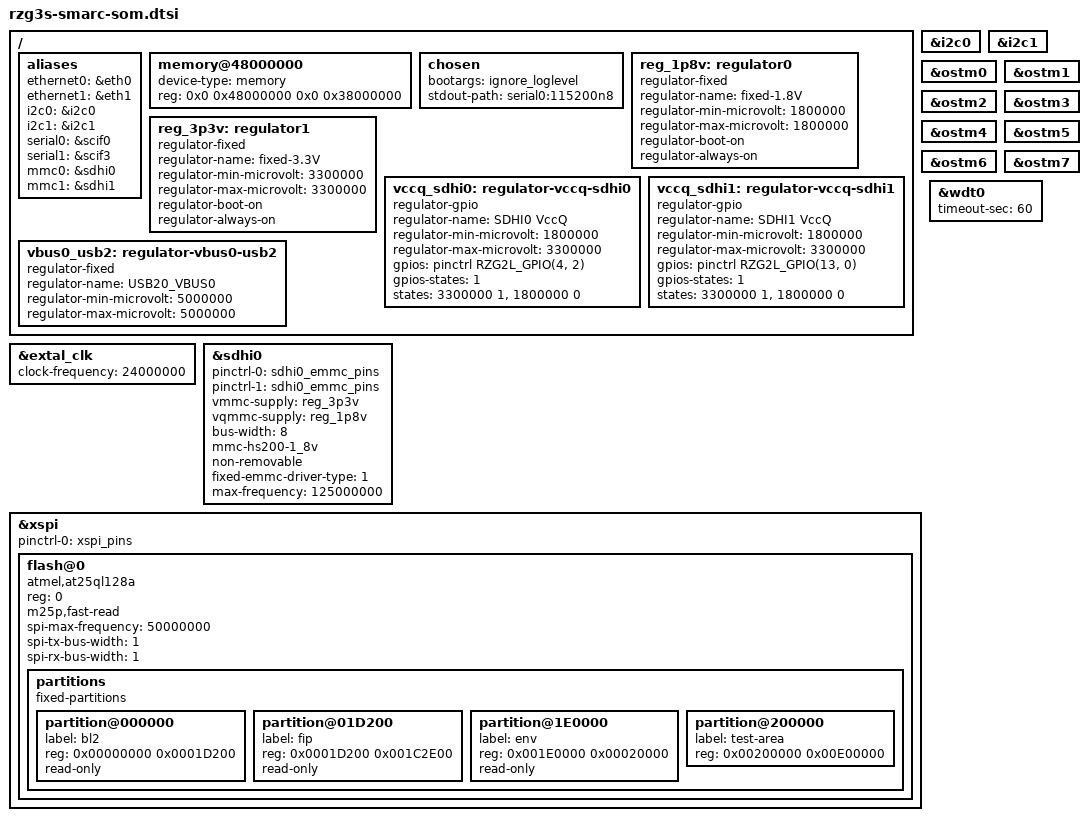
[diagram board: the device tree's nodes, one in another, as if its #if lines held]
// SPDX-License-Identifier: (GPL-2.0-only OR BSD-2-Clause)
/*
 * Device Tree Source for the RZ/G3S SMARC SOM
 *
 * Copyright (C) 2023 Renesas Electronics Corp.
 */

#include <dt-bindings/gpio/gpio.h>
#include <dt-bindings/pinctrl/rzg2l-pinctrl.h>

/ {
	aliases {
		ethernet0 = &eth0;
		ethernet1 = &eth1;
		i2c0 = &i2c0;
		i2c1 = &i2c1;
		serial0 = &scif0;
		serial1 = &scif3;
		mmc0 = &sdhi0;
		mmc1 = &sdhi1;
	};

	memory@48000000 {
		device-type = "memory";
		reg = <0x0 0x48000000 0x0 0x38000000>;
	};

	chosen {
		bootargs = "ignore_loglevel";
		stdout-path = "serial0:115200n8";
	};

	reg_1p8v: regulator0 {
		compatible = "regulator-fixed";
		regulator-name = "fixed-1.8V";
		regulator-min-microvolt = <1800000>;
		regulator-max-microvolt = <1800000>;
		regulator-boot-on;
		regulator-always-on;
	};

	reg_3p3v: regulator1 {
		compatible = "regulator-fixed";
		regulator-name = "fixed-3.3V";
		regulator-min-microvolt = <3300000>;
		regulator-max-microvolt = <3300000>;
		regulator-boot-on;
		regulator-always-on;
	};

	vccq_sdhi0: regulator-vccq-sdhi0 {
		compatible = "regulator-gpio";
		regulator-name = "SDHI0 VccQ";

		regulator-min-microvolt = <1800000>;
		regulator-max-microvolt = <3300000>;

		gpios = <&pinctrl RZG2L_GPIO(4, 2) GPIO_ACTIVE_HIGH>;
		gpios-states = <1>;
		states = <3300000 1>, <1800000 0>;
	};

	vccq_sdhi1: regulator-vccq-sdhi1 {
		compatible = "regulator-gpio";
		regulator-name = "SDHI1 VccQ";

		regulator-min-microvolt = <1800000>;
		regulator-max-microvolt = <3300000>;

		gpios = <&pinctrl RZG2L_GPIO(13, 0) GPIO_ACTIVE_HIGH>;
		gpios-states = <1>;
		states = <3300000 1>, <1800000 0>;
	};

	vbus0_usb2: regulator-vbus0-usb2 {
		compatible = "regulator-fixed";

		regulator-name = "USB20_VBUS0";
		regulator-min-microvolt = <5000000>;
		regulator-max-microvolt = <5000000>;
	};
};

&extal_clk {
	clock-frequency = <24000000>;
};

&i2c0 {
	status = "okay";
};

&i2c1 {
	status = "okay";
};

&ostm0 {
	status = "okay";
};

&ostm1 {
	status = "okay";
};

&ostm2 {
	status = "okay";
};

&ostm3 {
	status = "okay";
};

&ostm4 {
	status = "okay";
};

&ostm5 {
	status = "okay";
};

&ostm6 {
	status = "okay";
};

&ostm7 {
	status = "okay";
};

#if SW_SD0_DEV_SEL
&sdhi0 {
	pinctrl-0 = <&sdhi0_emmc_pins>;
	pinctrl-1 = <&sdhi0_emmc_pins>;
	pinctrl-names = "default", "state_uhs";

	vmmc-supply = <&reg_3p3v>;
	vqmmc-supply = <&reg_1p8v>;
	bus-width = <8>;
	mmc-hs200-1_8v;
	non-removable;
	fixed-emmc-driver-type = <1>;
	max-frequency = <125000000>;
	status = "okay";
};
#else
&sdhi0 {
	pinctrl-0 = <&sdhi0_pins>;
	pinctrl-1 = <&sdhi0_uhs_pins>;
	pinctrl-names = "default", "state_uhs";

	vmmc-supply = <&reg_3p3v>;
	vqmmc-supply = <&vccq_sdhi0>;
	bus-width = <4>;
	sd-uhs-sdr50;
	sd-uhs-sdr104;
	max-frequency = <125000000>;
	status = "okay";
};
#endif

&xspi {
	pinctrl-0 = <&xspi_pins>;
	pinctrl-names = "default";

	status = "okay";

	flash@0 {
		compatible = "atmel,at25ql128a", "jedec,spi-nor";
		reg = <0>;
		m25p,fast-read;
		spi-max-frequency = <50000000>;
		spi-tx-bus-width = <1>;
		spi-rx-bus-width = <1>;

		partitions {
			compatible = "fixed-partitions";
			#address-cells = <1>;
			#size-cells = <1>;

			partition@000000 {
				label = "bl2";
				reg = <0x00000000 0x0001D200>;
				read-only;
			};
			partition@01D200 {
				label = "fip";
				reg = <0x0001D200 0x001C2E00>;
				read-only;
			};
			partition@1E0000 {
				label = "env";
				reg = <0x001E0000 0x00020000>;
				read-only;
			};
			partition@200000 {
				label = "test-area";
				reg = <0x00200000 0x00E00000>;
			};
		};
	};
};

&wdt0 {
	status = "okay";
	timeout-sec = <60>;
};
